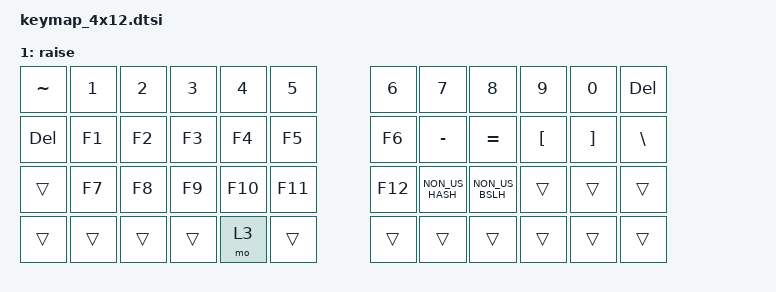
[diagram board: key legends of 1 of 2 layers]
/*
    Assemble the keymap from the abstracted alpha layer and other layers
    
    This is for a 12x4 (48 key) ortholinear board
    
    Works with Planck, Naked48, etc.
        
    Uses the core 3x5+2 alpha row defs and adds extra keys to fill out the keymap.
    The key (rows) values are defined in the corresponding HD-##.h file
    that should be included in the .keymap file before this.

    Layers are defined in moutis_config.dtsi so they can be
    referenced anywhere (keymap, behaviors, combos, adaptives)

*/

#define l_raise 1


// #include "layers_def.h" // layer def common core (3x5+2)

    keymap {
        compatible = "zmk,keymap";
        l_alpha {
            // ----------------------------------------------------------------------------------------------------------------------
            // |   X   |   W   |   M   |   G   |   J   |  TAB  | ------- | ------- | btldr |   #   |   .    |   /   |   "   |   '   |
            // |   S   |   C   |   N   |   T   |   K   | raise | ------- | ------- |  esc  |   ,   |   A    |   E   |   I   |   H   |
            // |   F   |   P   |   L   |   D   |   V   |   Z   | ------- | ------- |   Q   |   -   |   U    |   O   |   Y   |   B   |
            // |-------|  LEFT | RIGHT | BSPC  |   R   | SHIFT |   CTRL  |   ALT   |  GUI  | SPACE | RETURN |  UP   | DOWN  |-------|
            // ----------------------------------------------------------------------------------------------------------------------


            bindings = <
                HD_LT       &kp TAB                                                  &kp bootloader  HD_RT
                HD_LM       &mo 1                                                    &kp ESC         HD_RM
                HD_LB       &kp Z                                                    &kp Q           HD_RB
                &kp LEFT    &kp RIGHT   HD_LH       &kp LSHFT   &kp LCTRL   &kp RALT &kp RGUI        HD_RH   &kp UP  &kp DOWN
            >;
        };

        raise {
            // ----------------------------------------------------------------------------------------------------------
            // |   ~   |  1   |  2   |  3   |  4   |  5   |-------|-------|  6    |   7   |  8   |  9   |   0   |  DEL  |
            // |  DEL  |  F1  |  F2  |  F3  |  F4  |  F5  |-------|-------|  F6   |   -   |  =   |  [   |   ]   |   \   |
            // |       |  F7  |  F8  |  F9  |  F10 |  F11 |-------|-------|  F12  |   #   |  |   |      |       |       |
            // |-------|      |      |      |      |      |       |       |       |       |      |      |       |-------|
            bindings = <
                &kp TILDE &kp N1   &kp N2   &kp N3   &kp N4    &kp N5                &kp N6    &kp N7          &kp N8          &kp N9       &kp N0           &kp DEL
                &kp DEL   &kp F1   &kp F2   &kp F3   &kp F4    &kp F5                &kp F6    &kp MINUS       &kp EQUAL       &kp LBKT     &kp RBKT         &kp BSLH
                &trans    &kp F7   &kp F8   &kp F9   &kp F10   &kp F11               &kp F12   &kp NON_US_HASH &kp NON_US_BSLH &trans       &trans           &trans
                          &trans   &trans   &trans   &trans    &mo 3   &trans &trans &trans    &trans          &trans          &trans       &trans
            >;
        };
    };

